# nrf9230_engb_radiocore register map
Vendor: Nordic Semiconductor; Series: nRF92; File version: 1
CPU: CM33 r0p4, little endian, MPU, FPU, 3 interrupt priority bits, 480 interrupts, 4 SAU regions
Registers are 32-bit, read-write, reset 0x0 unless marked. A register's access mark holds for its fields unless they carry their own. Offsets are from the block's base; [hi:lo] are bit positions; lines under a group give offsets from that group; {n}, {i} and the like mark numbered series; 'fields as' and 'values as' point back to an identical list.

## ICACHEDATA_S — CACHEDATA
Base 0x03F00000
{0x0+0x40*i} SET[{i}] (i=0..1023) group — Unspecified
  {0x0+0x20*j} WAY[{j}] (j=0..1) group — Unspecified
    {0x0+8k} DU[{k}] (k=0..3) group — Unspecified
      {0x0+4l} DATA[{l}] (l=0..1) — Description collection: Cache data bits for DATA[q] in DU[p] (DataUnit) of SET[n], WAY[o].
        [31:0] Data ro

## ICACHEINFO_S — CACHEINFO
Base 0x03F10000
{0x0+8i} SET[{i}] (i=0..1023) group — Unspecified
  {0x0+4j} WAY[{j}] (j=0..1) group — Unspecified
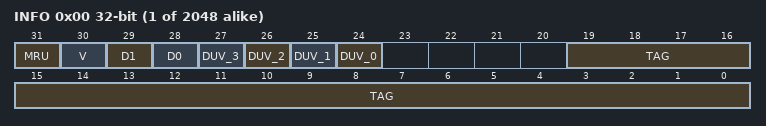
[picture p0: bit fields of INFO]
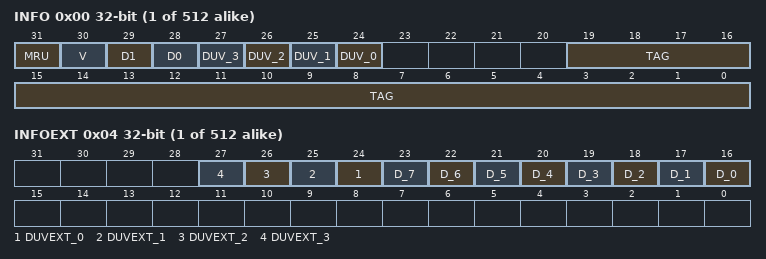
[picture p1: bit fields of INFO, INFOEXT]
    0x00 INFO — Description cluster: Cache information for SET[n], WAY[o].
      [31] MRU ro — Most recently used way.
        0=Way0 was most recently used; 1=Way1 was most recently used
      [30] V ro — Line valid bit.
        0=Invalid cache line; 1=Valid cache line
      [29] D1 ro — Dirty status of combined data unit 2 and 3.
        0=Clean data unit; 1=Dirty data unit
      [28] D0 ro — Dirty status of combined data unit 0 and 1.
        0=Clean data unit; 1=Dirty data unit
      [n+24] DUV_{n} ro (n=0..3) — Data unit valid info.
        0=Invalid data unit; 1=Valid data unit
      [19:0] TAG ro — Cache tag.

## DCACHEDATA_S — CACHEDATA
Base 0x23F00000
{0x0+0x40*i} SET[{i}] (i=0..255) group — Unspecified
  {0x0+0x20*j} WAY[{j}] (j=0..1) group — Unspecified
    {0x0+4k} DU[{k}] (k=0..7) group — Unspecified
      {0x0+4l} DATA[{l}] (l=0..0) — Description collection: Cache data bits for DATA[q] in DU[p] (DataUnit) of SET[n], WAY[o].
        [31:0] Data ro

## DCACHEINFO_S — CACHEINFO
Base 0x23F10000
{0x0+0x10*i} SET[{i}] (i=0..255) group — Unspecified
  {0x0+8j} WAY[{j}] (j=0..1) group — Unspecified
    0x00 INFO — Description cluster: Cache information for SET[n], WAY[o].
      [31] MRU ro — Most recently used way.
        0=Way0 was most recently used; 1=Way1 was most recently used
      [30] V ro — Line valid bit.
        0=Invalid cache line; 1=Valid cache line
      [29] D1 ro — Dirty status of combined data unit 2 and 3.
        0=Clean data unit; 1=Dirty data unit
      [28] D0 ro — Dirty status of combined data unit 0 and 1.
        0=Clean data unit; 1=Dirty data unit
      [n+24] DUV_{n} ro (n=0..3) — Data unit valid info.
        0=Invalid data unit; 1=Valid data unit
      [19:0] TAG ro — Cache tag.
    0x04 INFOEXT — Description cluster: Extended cache information for SET[n], WAY[o].
      [n+24] DUVEXT_{n} ro (n=0..3) — Extended data unit valid info.
        0=Invalid data unit; 1=Valid data unit
      [n+16] D_{n} ro (n=0..7) — Dirty status.
        0=Clean data unit; 1=Dirty data unit

## GLOBAL_STMDATA_NS — System Trace Macrocell data buffer 0
Base 0xA0000000
Same registers: GLOBAL_STMDATA_S 0xA0000000 (alternate view of GLOBAL_STMDATA_NS)
{0x0+0x1000000*i} DOMAIN[{i}] (i=0..15) group — Unspecified
  {0x0+j} DATA[{j}] (j=0..16777215) 8-bit — Description collection: STM extended stimulus port data buffer area for domain n. NonSecure writes to this region generates trace packets with id n+96. Secure writes to this region generates trace packets with id n+32.

## GLOBAL_TDDCONF_NS — TDDCONF 0
Base 0xBF001000
Same registers: GLOBAL_TDDCONF_S 0xBF001000 (alternate view of GLOBAL_TDDCONF_NS)
0x400 SYSPWRUPREQ — System power-up request
  [0] ACTIVE — Activate power-up request
    0=NotActive (Power-up request not active); 1=Active (Power-up request active)
0x404 DBGPWRUPREQ — Debug power-up request
  fields as SYSPWRUPREQ
0x408 TRACEPORTSPEED — Trace port trace clock speed
  [1:0] SPEED — Trace clock speed
    0=Speed100MHz; 1=Speed50MHz; 2=Speed25MHz; 3=Speed12500KHz (Speed 12.5MHz)
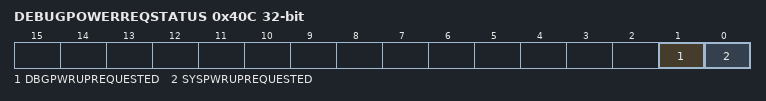
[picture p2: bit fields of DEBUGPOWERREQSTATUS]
0x40C DEBUGPOWERREQSTATUS ro — Combined effective system status of both SWJ-DP and TDDCONF registers originated power requests
  [1] DBGPWRUPREQUESTED — Debug domain powerup request status
    0=NoPowerReq (Power not requested); 1=Power requested
  [0] SYSPWRUPREQUESTED — System powerup request status
    0=NoPowerReq (Power not requested); 1=Power requested

## Notices in the file
Copyright (c) 2010 - 2024, Nordic Semiconductor ASA All rights reserved.
SPDX-License-Identifier: BSD-3-Clause
Redistribution and use in source and binary forms, with or without
modification, are permitted provided that the following conditions are met:
1. Redistributions of source code must retain the above copyright notice, this
list of conditions and the following disclaimer.
2. Redistributions in binary form must reproduce the above copyright
notice, this list of conditions and the following disclaimer in the
documentation and/or other materials provided with the distribution.
3. Neither the name of Nordic Semiconductor ASA nor the names of its
contributors may be used to endorse or promote products derived from this
software without specific prior written permission.
THIS SOFTWARE IS PROVIDED BY THE COPYRIGHT HOLDERS AND CONTRIBUTORS "AS IS"
AND ANY EXPRESS OR IMPLIED WARRANTIES, INCLUDING, BUT NOT LIMITED TO, THE
IMPLIED WARRANTIES OF MERCHANTABILITY, AND FITNESS FOR A PARTICULAR PURPOSE
ARE DISCLAIMED. IN NO EVENT SHALL NORDIC SEMICONDUCTOR ASA OR CONTRIBUTORS BE
LIABLE FOR ANY DIRECT, INDIRECT, INCIDENTAL, SPECIAL, EXEMPLARY, OR
CONSEQUENTIAL DAMAGES (INCLUDING, BUT NOT LIMITED TO, PROCUREMENT OF
SUBSTITUTE GOODS OR SERVICES; LOSS OF USE, DATA, OR PROFITS; OR BUSINESS
INTERRUPTION) HOWEVER CAUSED AND ON ANY THEORY OF LIABILITY, WHETHER IN
CONTRACT, STRICT LIABILITY, OR TORT (INCLUDING NEGLIGENCE OR OTHERWISE)
ARISING IN ANY WAY OUT OF THE USE OF THIS SOFTWARE, EVEN IF ADVISED OF THE
POSSIBILITY OF SUCH DAMAGE.
